# ATSAM4SP32A device description
Architecture: CORTEX-M4; Family: SAM4; Series: SAM4SP
Registers are 32-bit, read-write, no defined reset value unless marked. A register's access mark holds for its fields unless they carry their own. Offsets are from the block's base; [hi:lo] are bit positions; {n}, {i} and the like mark numbered series.

## CMCC — Cortex M Cache Controller
Instances: CMCC 0x4007C000
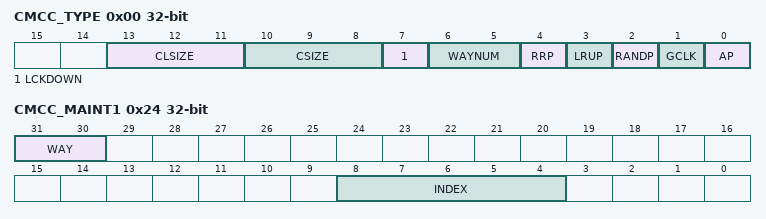
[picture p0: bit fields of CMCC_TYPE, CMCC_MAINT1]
0x00 CMCC_TYPE ro — Cache Type Register
  [13:11] CLSIZE — Cache Size
    0=CLSIZE_1KB (4 bytes); 1=CLSIZE_2KB (8 bytes); 2=CLSIZE_4KB (16 bytes); 3=CLSIZE_8KB (32 bytes)
  [10:8] CSIZE — Cache Size
    0=CSIZE_1KB (Cache Size 1 Kbytes); 1=CSIZE_2KB (Cache Size 2 Kbytes); 2=CSIZE_4KB (Cache Size 4 Kbytes); 3=CSIZE_8KB (Cache Size 8 Kbytes)
  [7] LCKDOWN — Lock Down Supported
  [6:5] WAYNUM — Number of Way
    0=DMAPPED (Direct Mapped Cache); 1=ARCH2WAY (2-WAY set associative); 2=ARCH4WAY (4-WAY set associative); 3=ARCH8WAY (8-WAY set associative)
  [4] RRP — Random Selection Policy Supported
  [3] LRUP — Least Recently Used Policy Supported
  [2] RANDP — Random Selection Policy Supported
  [1] GCLK — Dynamic Clock Gating Supported
  [0] AP — Access Port Access Allowed
0x04 CMCC_CFG — Cache Configuration Register
  [0] GCLKDIS — Disable Clock Gating
0x08 CMCC_CTRL wo — Cache Control Register
  [0] CEN — Cache Controller Enable
0x0C CMCC_SR ro — Cache Status Register
  [0] CSTS — Cache Controller Status
0x20 CMCC_MAINT0 wo — Cache Maintenance Register 0
  [0] INVALL — Cache Controller Invalidate All
0x24 CMCC_MAINT1 wo — Cache Maintenance Register 1
  [31:30] WAY — Invalidate Way
    {v}=Way {v} is selection for index invalidation (v=0..3)
  [8:4] INDEX — Invalidate Index
0x28 CMCC_MCFG — Cache Monitor Configuration Register
  [1:0] MODE — Cache Controller Monitor Counter Mode
    0=CYCLE_COUNT (Cycle counter); 1=IHIT_COUNT (Instruction hit counter); 2=DHIT_COUNT (Data hit counter)
0x2C CMCC_MEN — Cache Monitor Enable Register
  [0] MENABLE — Cache Controller Monitor Enable
0x30 CMCC_MCTRL wo — Cache Monitor Control Register
  [0] SWRST — Monitor
0x34 CMCC_MSR ro — Cache Monitor Status Register
  [31:0] EVENT_CNT — Monitor Event Counter

## CRCCU — Cyclic Redundancy Check Calculation Unit
Instances: CRCCU 0x40044000
0x00 CRCCU_DSCR — CRCCU Descriptor Base Register
  [31:9] DSCR — Descriptor Base Address
0x08 CRCCU_DMA_EN wo — CRCCU DMA Enable Register
  [0] DMAEN — DMA Enable Register
0x0C CRCCU_DMA_DIS wo — CRCCU DMA Disable Register
  [0] DMADIS — DMA Disable Register
0x10 CRCCU_DMA_SR ro — CRCCU DMA Status Register
  [0] DMASR — DMA Status Register
0x14 CRCCU_DMA_IER wo — CRCCU DMA Interrupt Enable Register
  [0] DMAIER — Interrupt Enable register
0x18 CRCCU_DMA_IDR wo — CRCCU DMA Interrupt Disable Register
  [0] DMAIDR — Interrupt Disable register
0x1C CRCCU_DMA_IMR ro — CRCCU DMA Interrupt Mask Register
  [0] DMAIMR — Interrupt Mask Register
0x20 CRCCU_DMA_ISR ro — CRCCU DMA Interrupt Status Register
  [0] DMAISR — Interrupt Status register
0x34 CRCCU_CR wo — CRCCU Control Register
  [0] RESET — CRC Computation Reset
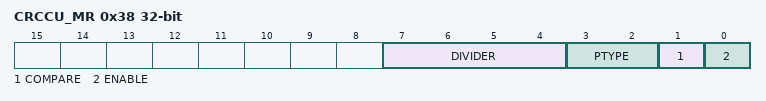
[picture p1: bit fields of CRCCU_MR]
0x38 CRCCU_MR — CRCCU Mode Register
  [7:4] DIVIDER — Request Divider
  [3:2] PTYPE — Primitive Polynomial
    0=CCITT8023 (Polynom 0x04C11DB7); 1=CASTAGNOLI (Polynom 0x1EDC6F41); 2=CCITT16 (Polynom 0x1021)
  [1] COMPARE — CRC Compare
  [0] ENABLE — CRC Enable
0x3C CRCCU_SR ro — CRCCU Status Register
  [31:0] CRC — Cyclic Redundancy Check Value
0x40 CRCCU_IER wo — CRCCU Interrupt Enable Register
  [0] ERRIER — CRC Error Interrupt Enable
0x44 CRCCU_IDR wo — CRCCU Interrupt Disable Register
  [0] ERRIDR — CRC Error Interrupt Disable
0x48 CRCCU_IMR ro — CRCCU Interrupt Mask Register
  [0] ERRIMR — CRC Error Interrupt Mask
0x4C CRCCU_ISR ro — CRCCU Interrupt Status Register
  [0] ERRISR — CRC Error Interrupt Status

## EFC — Embedded Flash Controller
Instances: EFC0 0x400E0A00, EFC1 0x400E0C00
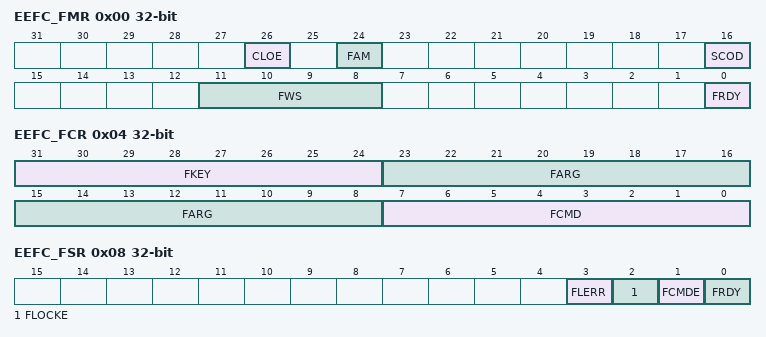
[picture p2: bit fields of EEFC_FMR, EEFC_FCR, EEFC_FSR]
0x00 EEFC_FMR — EEFC Flash Mode Register
  [26] CLOE — Code Loops Optimization Enable
  [24] FAM — Flash Access Mode
  [16] SCOD — Sequential Code Optimization Disable
  [11:8] FWS — Flash Wait State
  [0] FRDY — Ready Interrupt Enable
0x04 EEFC_FCR wo — EEFC Flash Command Register
  [31:24] FKEY — Flash Writing Protection Key
    90=PASSWD (The 0x5A value enables the command defined by the bits of the register. If the field is written with a different value, the write is not performed and no action is started.)
  [23:8] FARG — Flash Command Argument
  [7:0] FCMD — Flash Command
    0=GETD (Get Flash Descriptor); 1=WP (Write page); 2=WPL (Write page and lock); 3=EWP (Erase page and write page); 4=EWPL (Erase page and write page then lock); 5=EA (Erase all); 7=EPA (Erase Pages); 8=SLB (Set Lock Bit); 9=CLB (Clear Lock Bit); 10=GLB (Get Lock Bit); 11=SGPB (Set GPNVM Bit); 12=CGPB (Clear GPNVM Bit); 13=GGPB (Get GPNVM Bit); 14=STUI (Start Read Unique Identifier); 15=SPUI (Stop Read Unique Identifier); 16=GCALB (Get CALIB Bit); 17=ES (Erase Sector); 18=WUS (Write User Signature); 19=EUS (Erase User Signature); 20=STUS (Start Read User Signature); 21=SPUS (Stop Read User Signature)
0x08 EEFC_FSR ro — EEFC Flash Status Register
  [3] FLERR — Flash Error Status
  [2] FLOCKE — Flash Lock Error Status
  [1] FCMDE — Flash Command Error Status
  [0] FRDY — Flash Ready Status
0x0C EEFC_FRR ro — EEFC Flash Result Register
  [31:0] FVALUE — Flash Result Value
